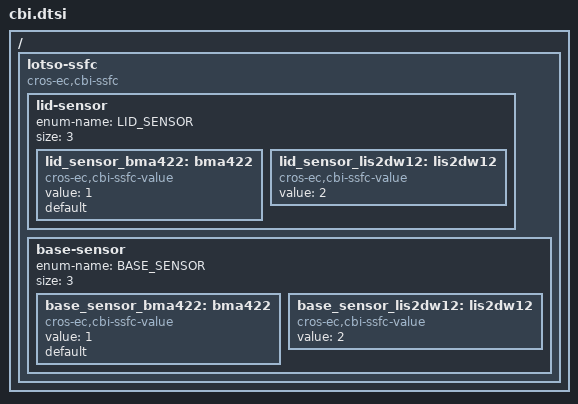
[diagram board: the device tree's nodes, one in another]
/* Copyright 2024 The ChromiumOS Authors
 * Use of this source code is governed by a BSD-style license that can be
 * found in the LICENSE file.
 */

/ {
	lotso-ssfc {
		compatible = "cros-ec,cbi-ssfc";

		/* SSFC field to identify lid motion sensor. */
		lid-sensor {
			enum-name = "LID_SENSOR";
			size = <3>;

			lid_sensor_bma422: bma422 {
				compatible = "cros-ec,cbi-ssfc-value";
				status = "okay";
				value = <1>;
				default;
			};
			lid_sensor_lis2dw12: lis2dw12 {
				compatible = "cros-ec,cbi-ssfc-value";
				status = "okay";
				value = <2>;
			};
		};

		/* SSFC field to identify base motion sensor. */
		base-sensor {
			enum-name = "BASE_SENSOR";
			size = <3>;

			base_sensor_bma422: bma422 {
				compatible = "cros-ec,cbi-ssfc-value";
				status = "okay";
				value = <1>;
				default;
			};
			base_sensor_lis2dw12: lis2dw12 {
				compatible = "cros-ec,cbi-ssfc-value";
				status = "okay";
				value = <2>;
			};
		};
	};
};
